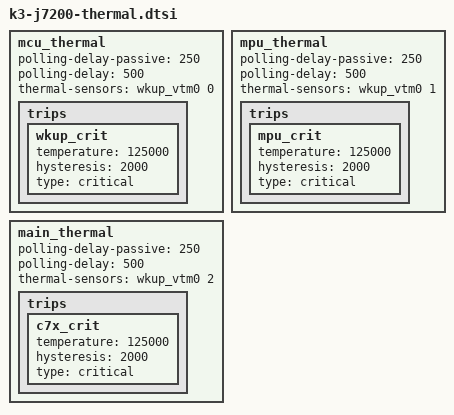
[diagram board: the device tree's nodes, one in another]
// SPDX-License-Identifier: GPL-2.0

#include <dt-bindings/thermal/thermal.h>

mcu_thermal: mcu_thermal {
	polling-delay-passive = <250>; /* milliseconds */
	polling-delay = <500>; /* milliseconds */
	thermal-sensors = <&wkup_vtm0 0>;

	trips {
		wkup_crit: wkup_crit {
			temperature = <125000>; /* milliCelsius */
			hysteresis = <2000>; /* milliCelsius */
			type = "critical";
		};
	};
};

mpu_thermal: mpu_thermal {
	polling-delay-passive = <250>; /* milliseconds */
	polling-delay = <500>; /* milliseconds */
	thermal-sensors = <&wkup_vtm0 1>;

	trips {
		mpu_crit: mpu_crit {
			temperature = <125000>; /* milliCelsius */
			hysteresis = <2000>; /* milliCelsius */
			type = "critical";
		};
	};
};

main_thermal: main_thermal {
	polling-delay-passive = <250>; /* milliseconds */
	polling-delay = <500>; /* milliseconds */
	thermal-sensors = <&wkup_vtm0 2>;

	trips {
		c7x_crit: c7x_crit {
			temperature = <125000>; /* milliCelsius */
			hysteresis = <2000>; /* milliCelsius */
			type = "critical";
		};
	};
};
